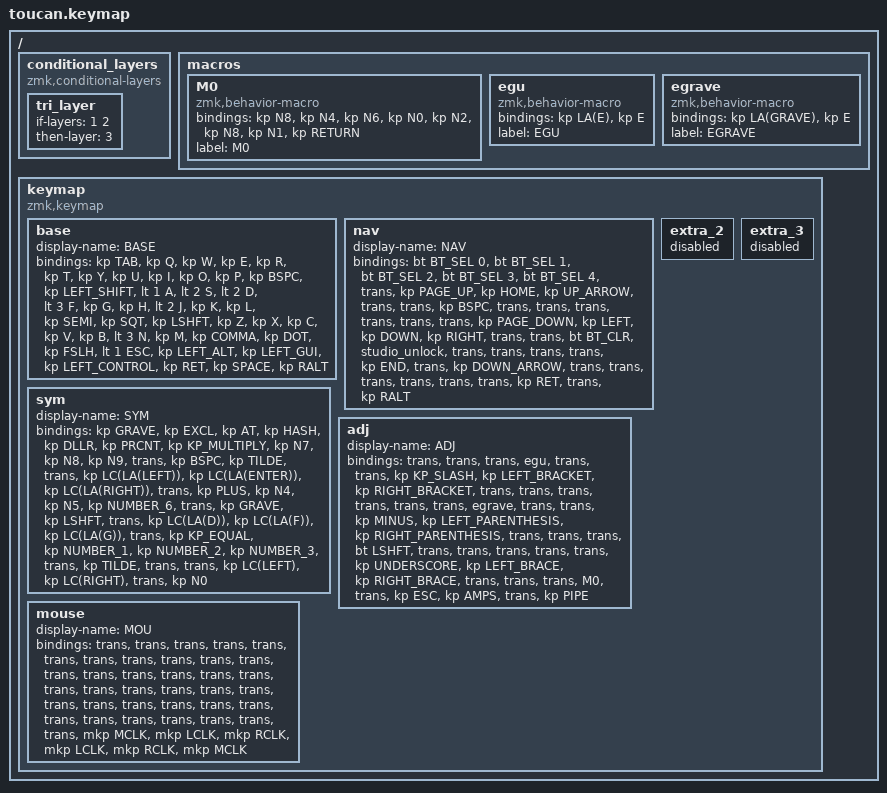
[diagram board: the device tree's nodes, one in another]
#include <behaviors.dtsi>
#include <dt-bindings/zmk/bt.h>
#include <dt-bindings/zmk/keys.h>
#include <dt-bindings/zmk/pointing.h>

#define BASE 0
#define NAV  1
#define SYM  2
#define ADJ  3

/ {
    conditional_layers {
        compatible = "zmk,conditional-layers";

        tri_layer {
            if-layers = <1 2>;
            then-layer = <3>;
        };
    };

    macros {
        M0: M0 {
            compatible = "zmk,behavior-macro";
            #binding-cells = <0>;
            bindings = <&kp N8 &kp N4 &kp N6 &kp N0 &kp N2 &kp N8 &kp N1 &kp RETURN>;
            label = "M0";
        };

        egu: egu {
            compatible = "zmk,behavior-macro";
            #binding-cells = <0>;
            bindings = <&kp LA(E) &kp E>;
            label = "EGU";
        };

        egrave: egrave {
            compatible = "zmk,behavior-macro";
            #binding-cells = <0>;
            bindings = <&kp LA(GRAVE) &kp E>;
            label = "EGRAVE";
        };
    };

    keymap {
        compatible = "zmk,keymap";

        base {
            display-name = "BASE";
            bindings = <
&kp TAB  &kp Q  &kp W  &kp E  &kp R  &kp T  &kp Y  &kp U  &kp I  &kp O  &kp P  &kp BSPC  &kp LEFT_SHIFT  &lt 1 A  &lt 2 S  &lt 2 D  &lt 3 F  &kp G  &kp H  &lt 2 J  &kp K  &kp L  &kp SEMI  &kp SQT  &kp LSHFT  &kp Z  &kp X  &kp C  &kp V  &kp B  &lt 3 N  &kp M  &kp COMMA  &kp DOT  &kp FSLH  &lt 1 ESC  &kp LEFT_ALT  &kp LEFT_GUI  &kp LEFT_CONTROL  &kp RET  &kp SPACE  &kp RALT
            >;
        };

        nav {
            display-name = "NAV";
            bindings = <
&bt BT_SEL 0  &bt BT_SEL 1  &bt BT_SEL 2  &bt BT_SEL 3  &bt BT_SEL 4  &trans  &kp PAGE_UP  &kp HOME  &kp UP_ARROW  &trans  &trans  &kp BSPC  &trans  &trans  &trans  &trans  &trans  &trans  &kp PAGE_DOWN  &kp LEFT  &kp DOWN  &kp RIGHT  &trans  &trans  &bt BT_CLR  &studio_unlock  &trans  &trans  &trans  &trans  &kp END  &trans  &kp DOWN_ARROW  &trans  &trans  &trans  &trans  &trans  &trans  &kp RET  &trans  &kp RALT
            >;
        };

        sym {
            display-name = "SYM";
            bindings = <
&kp GRAVE  &kp EXCL  &kp AT  &kp HASH  &kp DLLR  &kp PRCNT  &kp KP_MULTIPLY  &kp N7  &kp N8  &kp N9  &trans  &kp BSPC  &kp TILDE  &trans  &kp LC(LA(LEFT))  &kp LC(LA(ENTER))  &kp LC(LA(RIGHT))  &trans  &kp PLUS  &kp N4  &kp N5  &kp NUMBER_6  &trans  &kp GRAVE  &kp LSHFT  &trans  &kp LC(LA(D))  &kp LC(LA(F))  &kp LC(LA(G))  &trans  &kp KP_EQUAL  &kp NUMBER_1  &kp NUMBER_2  &kp NUMBER_3  &trans  &kp TILDE  &trans  &trans  &kp LC(LEFT)  &kp LC(RIGHT)  &trans  &kp N0
            >;
        };

        adj {
            display-name = "ADJ";
            bindings = <
&trans  &trans  &trans  &egu  &trans  &trans  &kp KP_SLASH  &kp LEFT_BRACKET  &kp RIGHT_BRACKET  &trans  &trans  &trans  &trans  &trans  &trans  &egrave  &trans  &trans  &kp MINUS  &kp LEFT_PARENTHESIS  &kp RIGHT_PARENTHESIS  &trans  &trans  &trans  &bt LSHFT  &trans  &trans  &trans  &trans  &trans  &kp UNDERSCORE  &kp LEFT_BRACE  &kp RIGHT_BRACE  &trans  &trans  &trans  &M0  &trans  &kp ESC  &kp AMPS  &trans  &kp PIPE
            >;
        };

        mouse {
            display-name = "MOU";
            bindings = <
&trans  &trans  &trans  &trans  &trans  &trans  &trans  &trans  &trans  &trans  &trans  &trans  &trans  &trans  &trans  &trans  &trans  &trans  &trans  &trans  &trans  &trans  &trans  &trans  &trans  &trans  &trans  &trans  &trans  &trans  &trans  &trans  &trans  &trans  &trans  &trans  &mkp MCLK  &mkp LCLK  &mkp RCLK  &mkp LCLK  &mkp RCLK  &mkp MCLK
            >;
        };

        extra_2 { status = "reserved"; };

        extra_3 { status = "reserved"; };
    };
};
